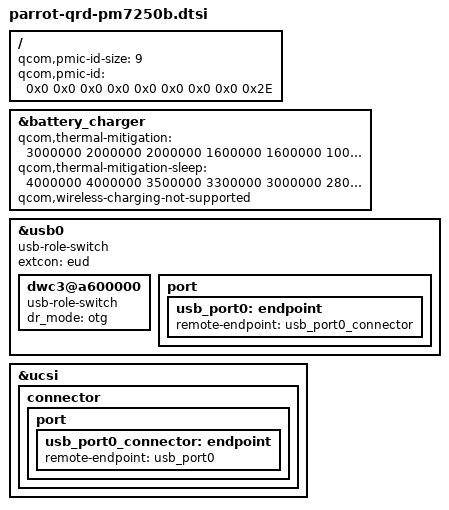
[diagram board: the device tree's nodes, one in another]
#include "parrot-pm7250b.dtsi"

/ {
	qcom,pmic-id-size = <9>;
	qcom,pmic-id = <0x0 0x0 0x0 0x0 0x0 0x0 0x0 0x0 0x2E>;
};

&battery_charger {
	qcom,thermal-mitigation = <3000000 2000000 2000000 1600000 1600000 1000000 1000000
				1000000 400000 400000 100000 100000 0 2000000
				1000000 600000 400000 200000 100000 100000 0 0>;
	qcom,thermal-mitigation-sleep = <4000000 4000000 3500000 3300000 3000000 2800000 2400000
				2200000 1600000 400000 100000 100000 0 2000000
				1000000 600000 400000 200000 100000 100000 0 0>;
	qcom,wireless-charging-not-supported;
};

&usb0 {
	usb-role-switch;
	extcon = <&eud>;

	dwc3@a600000 {
		usb-role-switch;
		dr_mode = "otg";
	};

	port {
		usb_port0: endpoint {
			remote-endpoint = <&usb_port0_connector>;
		};
	};
};

&ucsi {
	connector {
		port {
			usb_port0_connector: endpoint {
				remote-endpoint = <&usb_port0>;
			};
		};
	};
};
